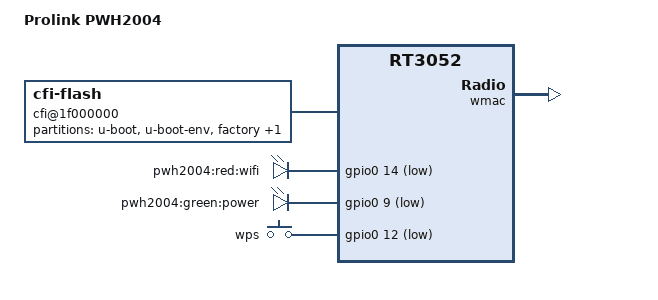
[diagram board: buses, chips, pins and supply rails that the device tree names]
/dts-v1/;

#include "rt3050.dtsi"

#include <dt-bindings/gpio/gpio.h>
#include <dt-bindings/input/input.h>

/ {
	compatible = "prolink,pwh2004", "ralink,rt3052-soc";
	model = "Prolink PWH2004";

	aliases {
		led-boot = &led_power;
		led-failsafe = &led_power;
		led-running = &led_power;
		led-upgrade = &led_power;
	};

	cfi@1f000000 {
		compatible = "cfi-flash";
		reg = <0x1f000000 0x800000>;
		bank-width = <2>;
		device-width = <2>;

		partitions {
			compatible = "fixed-partitions";
			#address-cells = <1>;
			#size-cells = <1>;

			partition@0 {
				label = "u-boot";
				reg = <0x0 0x30000>;
				read-only;
			};

			partition@30000 {
				label = "u-boot-env";
				reg = <0x30000 0x10000>;
				read-only;
			};

			factory: partition@40000 {
				label = "factory";
				reg = <0x40000 0x10000>;
				read-only;
			};

			partition@50000 {
				compatible = "denx,uimage";
				label = "firmware";
				reg = <0x50000 0x7b0000>;
			};
		};
	};

	gpio-leds {
		compatible = "gpio-leds";

		wifi {
			label = "pwh2004:red:wifi";
			gpios = <&gpio0 14 GPIO_ACTIVE_LOW>;
		};

		led_power: power {
			label = "pwh2004:green:power";
			gpios = <&gpio0 9 GPIO_ACTIVE_LOW>;
		};
	};

	gpio-keys-polled {
		compatible = "gpio-keys-polled";
		poll-interval = <20>;

		wps {
			label = "wps";
			gpios = <&gpio0 12 GPIO_ACTIVE_LOW>;
			linux,code = <KEY_RESTART>;
		};
	};
};

&pinctrl {
	state_default: pinctrl0 {
		gpio {
			ralink,group = "spi", "i2c", "jtag", "rgmii", "mdio", "uartf";
			ralink,function = "gpio";
		};
	};
};

&esw {
	mediatek,portmap = <0x2f>;
};

&wmac {
	ralink,mtd-eeprom = <&factory 0>;
};
